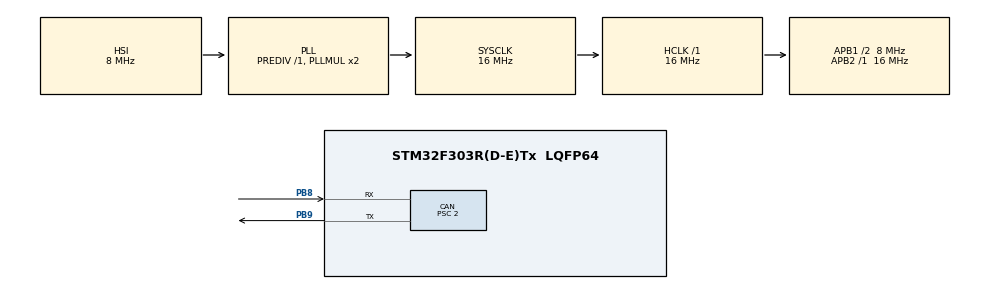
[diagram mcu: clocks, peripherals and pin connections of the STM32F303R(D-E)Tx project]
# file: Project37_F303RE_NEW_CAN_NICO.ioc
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CAN.BS1=CAN_BS1_13TQ
CAN.BS2=CAN_BS2_2TQ
CAN.CalculateBaudRate=250000
CAN.CalculateTimeBit=4000.00
CAN.CalculateTimeQuantum=250.0
CAN.Prescaler=2
Mcu.Family=STM32F3
Mcu.Name=STM32F303R(D-E)Tx
Mcu.Package=LQFP64
NVIC.PriorityGroup=NVIC_PRIORITYGROUP_0
NVIC.USB_LP_CAN_RX0_IRQn=true\:0\:0\:false\:false\:true\:true\:true
PB8.Mode=CAN_Activate
PB8.Signal=CAN_RX
PB9.Mode=CAN_Activate
PB9.Signal=CAN_TX
PF0-OSC_IN.Mode=HSE-External-Oscillator
PF0-OSC_IN.Signal=RCC_OSC_IN
PF1-OSC_OUT.Mode=HSE-External-Oscillator
PF1-OSC_OUT.Signal=RCC_OSC_OUT
ProjectManager.HeapSize=0x200
ProjectManager.StackSize=0x400
ProjectManager.TargetToolchain=EWARM V8.32
RCC.AHBFreq_Value=16000000
RCC.APB1CLKDivider=RCC_HCLK_DIV2
RCC.APB1Freq_Value=8000000
RCC.APB1TimFreq_Value=16000000
RCC.APB2Freq_Value=16000000
RCC.APB2TimFreq_Value=16000000
RCC.CortexFreq_Value=16000000
RCC.HCLKFreq_Value=16000000
RCC.HSE_VALUE=8000000
RCC.HSI_VALUE=8000000
RCC.LSE_VALUE=32768
RCC.PLLM=8
RCC.PLLN=336
RCC.PLLP=RCC_PLLP_DIV4
RCC.PLLQ=7
RCC.RCC_PLLsource_Clock_Source_FROM_HSE=RCC_HSE_PREDIV_DIV2
RCC.SYSCLKFreq_VALUE=16000000
RCC.SYSCLKSourceVirtual=RCC_SYSCLKSOURCE_PLLCLK
RCC.USBFreq_Value=16000000
board=NUCLEO-F303RE

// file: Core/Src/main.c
/* USER CODE BEGIN Header */
/**
  ******************************************************************************
  * @file           : main.c
  * @brief          : Main program body
  ******************************************************************************
  * @attention
  *
  * <h2><center>&copy; Copyright (c) 2021 STMicroelectronics.
  * All rights reserved.</center></h2>
  *
  * This software component is licensed by ST under BSD 3-Clause license,
  * the "License"; You may not use this file except in compliance with the
  * License. You may obtain a copy of the License at:
  *                        opensource.org/licenses/BSD-3-Clause
  *
  ******************************************************************************
  */
/* USER CODE END Header */
#include "main.h"

CAN_HandleTypeDef hcan;

/* USER CODE BEGIN PV */
CAN_HandleTypeDef hcan;
CAN_TxHeaderTypeDef pTxHeader;
CAN_RxHeaderTypeDef pRxHeader;
uint32_t pTxMailbox;
uint8_t a[]={0, 0, 0, 0, 0, 0, 0, 0};
uint8_t r[8];
CAN_FilterTypeDef sFilterConfig;
/* USER CODE END PV */

void SystemClock_Config(void);
static void MX_GPIO_Init(void);
static void MX_CAN_Init(void);

int main(void)
{

  /* MCU Configuration--------------------------------------------------------*/

  /* Reset of all peripherals, Initializes the Flash interface and the Systick. */
  HAL_Init();

  /* Configure the system clock */
  SystemClock_Config();

  /* Initialize all configured peripherals */
  MX_GPIO_Init();
  MX_CAN_Init();
  /* USER CODE BEGIN 2 */
pTxHeader.DLC = 8;
pTxHeader.IDE = CAN_ID_STD;
pTxHeader.RTR = CAN_RTR_DATA;
pTxHeader.StdId = 0x240;

sFilterConfig.FilterFIFOAssignment = CAN_FILTER_FIFO0;
sFilterConfig.FilterIdHigh = 0;
sFilterConfig.FilterIdLow = 0;
sFilterConfig.FilterMaskIdHigh = 0;
sFilterConfig.FilterIdLow = 0;
sFilterConfig.FilterScale = CAN_FILTERSCALE_32BIT;
sFilterConfig.FilterActivation = ENABLE;

HAL_CAN_ConfigFilter(&hcan, &sFilterConfig);

HAL_CAN_Start(&hcan);
HAL_CAN_ActivateNotification(&hcan, CAN_IT_RX_FIFO0_MSG_PENDING);
  /* USER CODE END 2 */

  /* Infinite loop */
  /* USER CODE BEGIN WHILE */
  while (1)
  {
     for(int i=0;i<8;i++){a[i]++;}
   HAL_Delay(1000);
     HAL_CAN_AddTxMessage(&hcan, &pTxHeader, a, &pTxMailbox);
    /* USER CODE END WHILE */

  }
}

void SystemClock_Config(void)
{
  RCC_OscInitTypeDef RCC_OscInitStruct = {0};
  RCC_ClkInitTypeDef RCC_ClkInitStruct = {0};

  /** Initializes the RCC Oscillators according to the specified parameters
  * in the RCC_OscInitTypeDef structure.
  */
  RCC_OscInitStruct.OscillatorType = RCC_OSCILLATORTYPE_HSI;
  RCC_OscInitStruct.HSIState = RCC_HSI_ON;
  RCC_OscInitStruct.HSICalibrationValue = RCC_HSICALIBRATION_DEFAULT;
  RCC_OscInitStruct.PLL.PLLState = RCC_PLL_ON;
  RCC_OscInitStruct.PLL.PLLSource = RCC_PLLSOURCE_HSI;
  RCC_OscInitStruct.PLL.PLLMUL = RCC_PLL_MUL2;
  RCC_OscInitStruct.PLL.PREDIV = RCC_PREDIV_DIV1;
  if (HAL_RCC_OscConfig(&RCC_OscInitStruct) != HAL_OK)
  {
    Error_Handler();
  }
  /** Initializes the CPU, AHB and APB buses clocks
  */
  RCC_ClkInitStruct.ClockType = RCC_CLOCKTYPE_HCLK|RCC_CLOCKTYPE_SYSCLK
                              |RCC_CLOCKTYPE_PCLK1|RCC_CLOCKTYPE_PCLK2;
  RCC_ClkInitStruct.SYSCLKSource = RCC_SYSCLKSOURCE_PLLCLK;
  RCC_ClkInitStruct.AHBCLKDivider = RCC_SYSCLK_DIV1;
  RCC_ClkInitStruct.APB1CLKDivider = RCC_HCLK_DIV2;
  RCC_ClkInitStruct.APB2CLKDivider = RCC_HCLK_DIV1;

  if (HAL_RCC_ClockConfig(&RCC_ClkInitStruct, FLASH_LATENCY_0) != HAL_OK)
  {
    Error_Handler();
  }
}

static void MX_CAN_Init(void)
{

  hcan.Instance = CAN;
  hcan.Init.Prescaler = 2;
  hcan.Init.Mode = CAN_MODE_NORMAL;
  hcan.Init.SyncJumpWidth = CAN_SJW_1TQ;
  hcan.Init.TimeSeg1 = CAN_BS1_13TQ;
  hcan.Init.TimeSeg2 = CAN_BS2_2TQ;
  hcan.Init.TimeTriggeredMode = DISABLE;
  hcan.Init.AutoBusOff = DISABLE;
  hcan.Init.AutoWakeUp = DISABLE;
  hcan.Init.AutoRetransmission = DISABLE;
  hcan.Init.ReceiveFifoLocked = DISABLE;
  hcan.Init.TransmitFifoPriority = DISABLE;
  if (HAL_CAN_Init(&hcan) != HAL_OK)
  {
    Error_Handler();
  }

}

static void MX_GPIO_Init(void)
{

  /* GPIO Ports Clock Enable */
  __HAL_RCC_GPIOF_CLK_ENABLE();
  __HAL_RCC_GPIOB_CLK_ENABLE();

}

void Error_Handler(void)
{
  __disable_irq();
  while (1)
  {
  }
}

/************************ (C) COPYRIGHT STMicroelectronics *****END OF FILE****/
